# AE402FA0E5597LE0_CM55_HP_View register map
Vendor: Alif Semiconductor; Series: E4; File version: 1.0
CPU: CM55 r1p0, selectable endian, MPU, FPU, double-precision FPU, DSP, VTOR, 8 interrupt priority bits, 1 SAU regions
Registers are 32-bit, read-write, reset 0x0 unless marked. A register's access mark holds for its fields unless they carry their own. Offsets are from the block's base; [hi:lo] are bit positions; {n}, {i} and the like mark numbered series; 'fields as' and 'values as' point back to an identical list.

## ISP (part 2 of 2)
Base 0x49046000
0xA00 ISP_CC_COEFF_0 reset 0x21
  [8:0] CC_COEFF0 — Coefficient 0 for color space conversion
0xA04 ISP_CC_COEFF_1 reset 0x40
  [8:0] CC_COEFF1 — Coefficient 1 for color space conversion
0xA08 ISP_CC_COEFF_2 reset 0xD
  [8:0] CC_COEFF2 — Coefficient 2 for color space conversion
0xA0C ISP_CC_COEFF_3 reset 0x1ED
  [8:0] CC_COEFF3 — Coefficient 3 for color space conversion
0xA10 ISP_CC_COEFF_4 reset 0x1DB
  [8:0] CC_COEFF4 — Coefficient 4 for color space conversion
0xA14 ISP_CC_COEFF_5 reset 0x38
  [8:0] CC_COEFF5 — Coefficient 5 for color space conversion
0xA18 ISP_CC_COEFF_6 reset 0x38
  [8:0] CC_COEFF6 — Coefficient 6 for color space conversion
0xA1C ISP_CC_COEFF_7 reset 0x1D1
  [8:0] CC_COEFF7 — Coefficient 7 for color space conversion
0xA20 ISP_CC_COEFF_8 reset 0x1F7
  [8:0] CC_COEFF8 — Coefficient 8 for color space conversion
0xA24 ISP_FORMAT_CONV_CTRL
  [0] Y_ONLY
    0=Output y and c data from format conv; 1=Only output Y data
0xA30 ISP_CT_COEFF_0 reset 0x80
  [10:0] CT_COEFF0 — Coefficient for cross talk matrix. Values are 11-bit signed fixed-point numbers with 4 bit integer and 7 bit fractional part, ranging from -8 (0x400) to +7.992 (0x3FF). 0 is represented by 0x000 and a coefficient value of 1 as 0x080.
{0xA30+4i} ISP_CT_COEFF_{i} (i=1..3)
  [10:0] CT_COEFF{i} — Coefficient for cross talk matrix. Values are 11-bit signed fixed-point numbers with 4 bit integer and 7 bit fractional part, ranging from -8 (0x400) to +7.992 (0x3FF). 0 is represented by 0x000 and a coefficient value of 1 as 0x080.
0xA40 ISP_CT_COEFF_4 reset 0x80
  [10:0] CT_COEFF4 — Coefficient for cross talk matrix. Values are 11-bit signed fixed-point numbers with 4 bit integer and 7 bit fractional part, ranging from -8 (0x400) to +7.992 (0x3FF). 0 is represented by 0x000 and a coefficient value of 1 as 0x080.
{0xA30+4i} ISP_CT_COEFF_{i} (i=5..7)
  fields as ISP_CT_COEFF_1
0xA50 ISP_CT_COEFF_8 reset 0x80
  [10:0] CT_COEFF8 — Coefficient for cross talk matrix. Values are 11-bit signed fixed-point numbers with 4 bit integer and 7 bit fractional part, ranging from -8 (0x400) to +7.992 (0x3FF). 0 is represented by 0x000 and a coefficient value of 1 as 0x080.
0xA54 ISP_CT_OFFSET_R
  [11:0] CT_OFFSET_R — Red offset for the cross talk matrix. Two's complement integer number ranging from -2048 (0x800) to 2047 (0x7FF). 0 is represented as 0x000.
0xA58 ISP_CT_OFFSET_G
  [11:0] CT_OFFSET_G — Green offset for the cross talk matrix. Two's complement integer number ranging from -2048 (0x800) to 2047 (0x7FF). 0 is represented as 0x000.
0xA5C ISP_CT_OFFSET_B
  [11:0] CT_OFFSET_B — Blue offset for the cross talk matrix. Two's complement integer number ranging from -2048 (0x800) to 2047 (0x7FF). 0 is represented as 0x000.
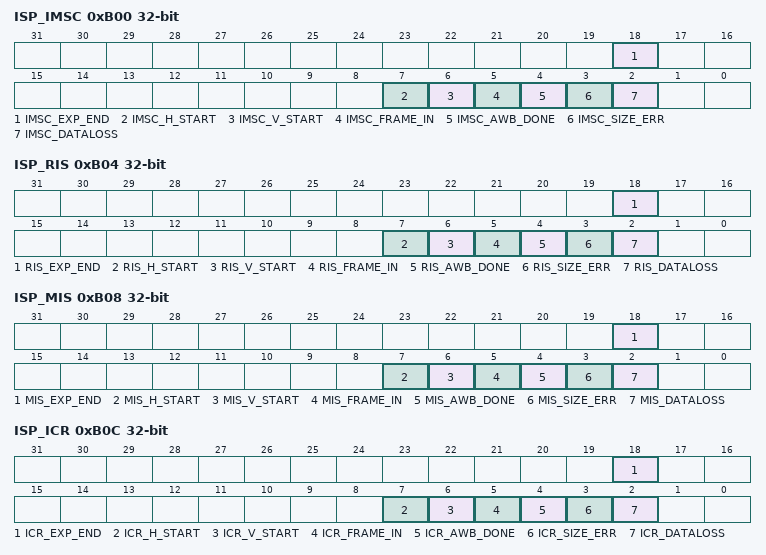
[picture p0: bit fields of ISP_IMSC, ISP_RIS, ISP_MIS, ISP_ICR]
0xB00 ISP_IMSC
  [18] IMSC_EXP_END — Exposure measurement complete
  [7] IMSC_H_START
    0=Mask out; 1=Enable interrupt
  [6] IMSC_V_START
    0=Mask out; 1=Enable interrupt
  [5] IMSC_FRAME_IN
    0=Mask out; 1=Enable interrupt
  [4] IMSC_AWB_DONE
    0=Mask out; 1=Enable interrupt
  [3] IMSC_SIZE_ERR
    0=Mask out; 1=Enable interrupt
  [2] IMSC_DATALOSS
    0=Mask out; 1=Enable interrupt
0xB04 ISP_RIS ro
  [18] RIS_EXP_END — Exposure measurement complete
  [7] RIS_H_START — Start edge of h_sync
  [6] RIS_V_START — Start edge of v_sync
  [5] RIS_FRAME_IN — Sampled input frame is complete
  [4] RIS_AWB_DONE — White balancing measurement cycle is complete results can be read out
  [3] RIS_SIZE_ERR — Picture size violation occurred incorrect programming
  [2] RIS_DATALOSS — Loss of data occurred within a line, processing failure
0xB08 ISP_MIS ro
  [18] MIS_EXP_END — Exposure measurement complete
  [7] MIS_H_START — Start edge of h_sync
  [6] MIS_V_START — Start edge of v_sync
  [5] MIS_FRAME_IN — Sampled input frame is complete
  [4] MIS_AWB_DONE — White balancing measurement cycle is complete results can be read out
  [3] MIS_SIZE_ERR — Picture size violation occurred incorrect programming
  [2] MIS_DATALOSS — Loss of data occurred within a line, processing failure
0xB0C ISP_ICR wo
  [18] ICR_EXP_END — Clear interrupt
  [7] ICR_H_START — Clear interrupt
  [6] ICR_V_START — Clear interrupt
  [5] ICR_FRAME_IN — Clear interrupt
  [4] ICR_AWB_DONE — Clear interrupt
  [3] ICR_SIZE_ERR — Clear interrupt
  [2] ICR_DATALOSS — Clear interrupt
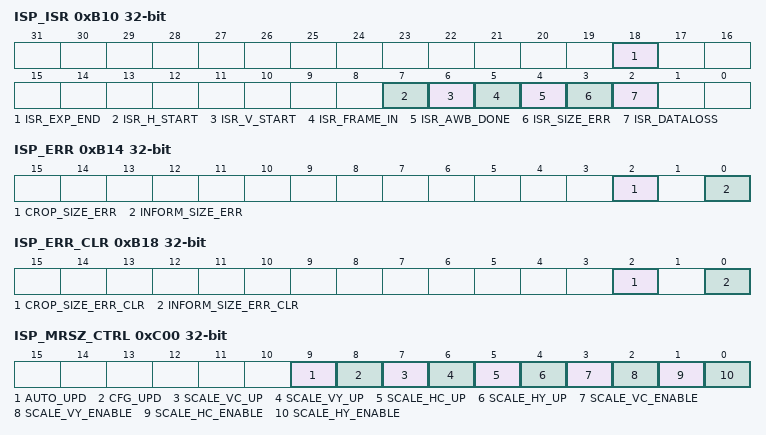
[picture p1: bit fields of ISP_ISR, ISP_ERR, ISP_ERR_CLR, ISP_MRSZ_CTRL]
0xB10 ISP_ISR wo
  [18] ISR_EXP_END — Set interrupt
  [7] ISR_H_START — Set interrupt
  [6] ISR_V_START — Set interrupt
  [5] ISR_FRAME_IN — Set interrupt
  [4] ISR_AWB_DONE — Set interrupt
  [3] ISR_SIZE_ERR — Set interrupt
  [2] ISR_DATALOSS — Set interrupt
0xB14 ISP_ERR ro
  [2] CROP_SIZE_ERR — Size error is generated in crop submodule
  [0] INFORM_SIZE_ERR — Size error is generated in inform submodule
0xB18 ISP_ERR_CLR wo
  [2] CROP_SIZE_ERR_CLR — Size error is cleared
  [0] INFORM_SIZE_ERR_CLR — Size error is cleared
0xC00 ISP_MRSZ_CTRL
  [9] AUTO_UPD
    0=No update; 1=Update shadow registers at frame end
  [8] CFG_UPD — Write 0: Nothing happens Write 1: Update shadow registers Read: Always 0
  [7] SCALE_VC_UP
    0=Vertical chrominance downscaling selected; 1=Vertical chrominance upscaling selected
  [6] SCALE_VY_UP
    0=Vertical luminance downscaling selected; 1=Vertical luminance upscaling selected
  [5] SCALE_HC_UP
    0=Horizontal chrominance downscaling selected; 1=Horizontal chrominance upscaling selected
  [4] SCALE_HY_UP
    0=Horizontal luminance downscaling selected; 1=Horizontal luminance upscaling selected
  [3] SCALE_VC_ENABLE — Vertical chrominance scaling unit
    0=Bypass; 1=Enable
  [2] SCALE_VY_ENABLE — Vertical luminance scaling unit
    0=Bypass; 1=Enable
  [1] SCALE_HC_ENABLE — Horizontal chrominance scaling unit
    0=Bypass; 1=Enable
  [0] SCALE_HY_ENABLE — Horizontal luminance scaling unit
    0=Bypass; 1=Enable
0xC04 ISP_MRSZ_SCALE_HY
  [15:0] SCALE_HY — This register is set to the horizontal luminance downscale factor or to the reciprocal of the horizontal luminance upscale factor.
0xC08 ISP_MRSZ_SCALE_HCB
  [15:0] SCALE_HCB — This register is set to the horizontal Cb downscale factor or to the reciprocal of the horizontal Cb upscale factor.
0xC0C ISP_MRSZ_SCALE_HCR
  [15:0] SCALE_HCR — This register is set to the horizontal Cr downscale factor or to the reciprocal of the horizontal Cr upscale factor.
0xC10 ISP_MRSZ_SCALE_VY
  [15:0] SCALE_VY — This register is set to the vertical luminance downscale factor or to the reciprocal of the vertical luminance upscale factor.
0xC14 ISP_MRSZ_SCALE_VC
  [15:0] SCALE_VC — This register is set to the vertical chrominance downscale factor or to the reciprocal of the vertical chrominance upscale factor.
0xC18 ISP_MRSZ_PHASE_HY
  [15:0] PHASE_HY — This register is set to the horizontal luminance phase offset.
0xC1C ISP_MRSZ_PHASE_HC
  [15:0] PHASE_HC — This register is set to the horizontal chrominance phase offset.
0xC20 ISP_MRSZ_PHASE_VY
  [15:0] PHASE_VY — This register is set to the vertical luminance phase offset.
0xC24 ISP_MRSZ_PHASE_VC
  [15:0] PHASE_VC — This register is set to the vertical chrominance phase offset.
0xC28 ISP_MRSZ_SCALE_LUT_ADDR
  [5:0] SCALE_LUT_ADDR — Pointer to entry of upscaling lookup table.
0xC2C ISP_MRSZ_SCALE_LUT
  [5:0] SCALE_LUT — Entry of lookup table at position scale_lut_addr. The lookup table must be filled with appropriate values before the upscaling functionality can be used.
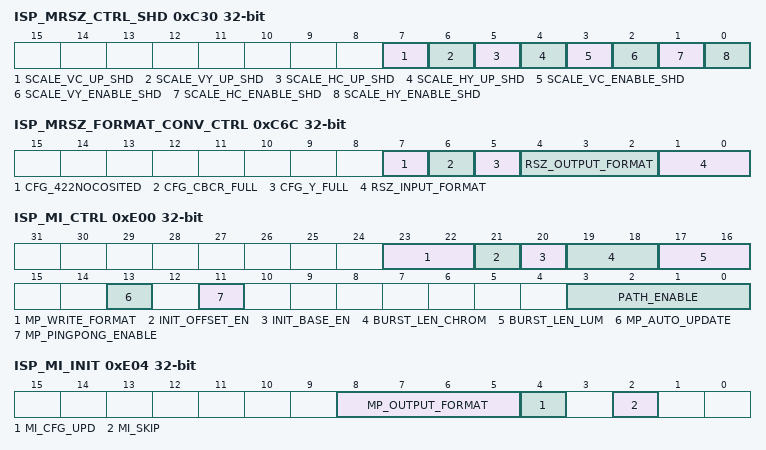
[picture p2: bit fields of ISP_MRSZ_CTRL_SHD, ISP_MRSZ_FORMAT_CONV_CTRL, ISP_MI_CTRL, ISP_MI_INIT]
0xC30 ISP_MRSZ_CTRL_SHD ro
  [7] SCALE_VC_UP_SHD
    values as ISP_MRSZ_CTRL.SCALE_VC_UP
  [6] SCALE_VY_UP_SHD
    values as ISP_MRSZ_CTRL.SCALE_VY_UP
  [5] SCALE_HC_UP_SHD
    values as ISP_MRSZ_CTRL.SCALE_HC_UP
  [4] SCALE_HY_UP_SHD
    values as ISP_MRSZ_CTRL.SCALE_HY_UP
  [3] SCALE_VC_ENABLE_SHD — Vertical chrominance scaling unit
    0=Bypass; 1=Enable
  [2] SCALE_VY_ENABLE_SHD — Vertical luminance scaling unit
    0=Bypass; 1=Enable
  [1] SCALE_HC_ENABLE_SHD — Horizontal chrominance scaling unit
    0=Bypass; 1=Enable
  [0] SCALE_HY_ENABLE_SHD — Horizontal luminance scaling unit
    0=Bypass; 1=Enable
0xC34 ISP_MRSZ_SCALE_HY_SHD ro
  [15:0] SCALE_HY_SHD — This register is set to the horizontal luminance downscale factor or to the reciprocal of the horizontal luminance upscale factor.
0xC38 ISP_MRSZ_SCALE_HCB_SHD ro
  [15:0] SCALE_HCB_SHD — This register is set to the horizontal Cb downscale factor or to the reciprocal of the horizontal Cb upscale factor.
0xC3C ISP_MRSZ_SCALE_HCR_SHD ro
  [15:0] SCALE_HCR_SHD — This register is set to the horizontal Cr downscale factor or to the reciprocal of the horizontal Cr upscale factor.
0xC40 ISP_MRSZ_SCALE_VY_SHD ro
  [15:0] SCALE_VY_SHD — This register is set to the vertical luminance downscale factor or to the reciprocal of the vertical luminance upscale factor.
0xC44 ISP_MRSZ_SCALE_VC_SHD ro
  [15:0] SCALE_VC_SHD — This register is set to the vertical chrominance downscale factor or to the reciprocal of the vertical chrominance upscale factor.
0xC48 ISP_MRSZ_PHASE_HY_SHD ro
  [15:0] PHASE_HY_SHD — This register is set to the horizontal luminance phase offset.
0xC4C ISP_MRSZ_PHASE_HC_SHD ro
  [15:0] PHASE_HC_SHD — This register is set to the horizontal chrominance phase offset.
0xC50 ISP_MRSZ_PHASE_VY_SHD ro
  [15:0] PHASE_VY_SHD — This register is set to the vertical luminance phase offset.
0xC54 ISP_MRSZ_PHASE_VC_SHD ro
  [15:0] PHASE_VC_SHD — This register is set to the vertical chrominance phase offset.
0xC6C ISP_MRSZ_FORMAT_CONV_CTRL
  [7] CFG_422NOCOSITED — so modified interpolation is activated Note: the programmed value becomes effective immediately after this register is set. Therefore, only write to this register if no picture data is sent to the Self Path.
    0=YCbCr422 data are co-sited (Y0 Cb0 and Cr0 are sampled at the same position); 1=YCbCr422 data are non_co-sited (Cb and Cr samples are centered between Y samples)
  [6] CFG_CBCR_FULL — Note: the programmed value becomes effective immediately after this register is set. Therefore, only write to this register if no picture data is sent to the Self Path.
    0=CbCr has a compressed range of [16..240]; 1=CbCr has full range [0..255]
  [5] CFG_Y_FULL — Note: the programmed value becomes effective immediately after this register is set. Therefore, only write to this register if no picture data is sent to the Self Path.
    0=Y has a compressed range of [16..235]; 1=Y has full range [0..255]
  [4:2] RSZ_OUTPUT_FORMAT — Main Resize output format Reserved
    0=Val_0b000 (YCbCr 4:0:0); 1=Val_0b001 (YCbCr 4:2:0); 2=Val_0b010 (YCbCr 4:2:2); 3=Val_0b011 (YCbCr 4:4:4); 4=Val_0b100 (RGB565,not supported); 5=Val_0b101 (RGB666,not supported); 6=Val_0b110 (RGB888)
  [1:0] RSZ_INPUT_FORMAT — Main resize input format
    0=Val_0b00 (YCbCr 4:0:0); 1=Val_0b01 (YCbCr 4:2:0); 2=Val_0b10 (YCbCr 4:2:2); 3=Val_0b11 (YCbCr 4:4:4)
0xE00 ISP_MI_CTRL
  [23:22] MP_WRITE_FORMAT — Defines how YCbCr main picture data is written to memory. In YCbCr mode the following meaning is applicable: 00: Planar 01: Semi planar, for YCbCr 4:2:x 10: Interleaved (combined), for YCbCr 4:2:2 only 11: YUV only In RAW data mode the following meaning is applicable: 00: RAW 8 bit 01: RAW 10 bit 10: RAW 12bit 11: Reserved Note: Programmed value becomes effective immediately. So write to the register only if no picture data is sent to the main path.
  [21] INIT_OFFSET_EN — Enables updating of the offset counters shadow registers for main and self picture to the programmed register init values. MI_MP/SP_Y/CB/CR_OFFS_CNT_INIT-&gt MI_MP/SP_Y/CB/CR_OFFS_CNT_SHD The update will be executed either when a forced software update occurs (in register ISP_MI_INIT bit cfg_upd = 1) or when an automatic config update signal arrives at the MI input port. The latter is split into main and self picture. So only the corresponding main/self shadow registers are affected. After a picture skip has been performed init_offset_en selects between skip restart and skip init mode (see bit skip in register ISP_MI_INIT).
  [20] INIT_BASE_EN — Enables updating of the base address and buffer size shadow registers for main and self picture to the programmed register init values. MI_MP/SP_Y/CB/CR_BASE_AD_INIT -&gt MI_MP/SP_Y/CB/CR_BASE_AD_SHD MI_MP/SP_Y/CB/CR_SIZE_INIT-&gt MI_MP/SP_Y/CB/CR_SIZE_SHD The update will be executed either when a forced software update occurs (in register ISP_MI_INIT bit cfg_upd = 1) or when an automatic config update signal arrives at the MI input port. The latter is split into main and self picture. So only the corresponding main/self shadow registers are affected.
  [19:18] BURST_LEN_CHROM — Burst length for Cb or Cr data affecting write port. Ignored if 8- or 16-beat bursts are not supported. If rotation is active, then only 4-beat bursts will be generated in self path, regardless of the setting here. Note: Programmed value becomes effective immediately. So write to the register only if no picture data is sent to the main and self path.
    0=Val_0b00 (4-beat bursts); 1=Val_0b01 (8-beat bursts); 2=Val_0b10 (16-beat bursts)
  [17:16] BURST_LEN_LUM — Burst length for Y, JPEG, or raw data affecting write port. Ignored if 8- or 16-beat bursts are not supported. Note: Programmed value becomes effective immediately. So write to the register only if no picture data is sent to the main and self path.
    values as BURST_LEN_CHROM
  [13] MP_AUTO_UPDATE — Automatic update of configuration registers for main path at frame end.
    0=Disabled; 1=Enabled
  [11] MP_PINGPONG_ENABLE — Pingpong mode of configuration registers for main path at frame end.
    0=Disabled; 1=Enabled
  [3:0] PATH_ENABLE — Enables data paths of Memory Interface according to the following table: The programmed value becomes effective (visible in shadow register) after a soft reset, a forced software update or an automatic configuration update. Affects the MI_IN and MI_OUT module.
    0=Val_0b0000 (Disabled, no data is transferred); 1=Val_0b0001 (YUV data output, mainpath only (mp_enable only)); 8=Val_0b1000 (RAW data output, mainpath only (raw_enable only))
0xE04 ISP_MI_INIT
  [8:5] MP_OUTPUT_FORMAT — Selects output format of main picture.
    0=Val_0b0000 (YCbCr 4:0:0); 1=Val_0b0001 (YCbCr 4:2:0); 2=Val_0b0010 (YCbCr 4:2:2); 5=Val_0b0101 (RAW 8); 4=Val_0b0100 (RAW 12); 7=Val_0b0111 (RAW 10)
  [4] MI_CFG_UPD — Forced configuration update. Leads to an immediate update of the shadow registers. Depending on the two init enable bits in the ISP_MI_CTRL register (init_offset_en and init_base_en) the offset counter, base address and buffer size shadow registers are also updated.
  [2] MI_SKIP — Skip of current or next starting main picture: - Aborts writing of main picture image data of the current frame to RAM (after the current burst transmission has been completed). Further main picture data up to the end of the current frame are discarded. - No further macroblock line interrupt (mblk_line), no wrap around interrupt for main picture (wrap_mp_y/cb/cr) and no fill level interrupt (fill_mp_y) are generated. - Skip does not affect the generation of the main path frame end interrupt (mp_frame_end). - Skip does not affect the processing of self picture and its corresponding interrupts namely the self path frame end interrupt (sp_frame_end). - The byte counter (register ISP_MI_BYTE_CNT) is not affected. It produces the correct number of JPEG or RAW data bytes at the end of the current (skipped) frame. - After a skip has been performed, the offset counter for the main picture at the start of the following frame are set depending on the bit init_offset_en in register ISP_MI_CTRL: - Skip restart mode (init_offset_en = 0) The offset counters of the main picture are restarted at the old start values of the previous skipped frame. - Skip init mode (init_offset_en = 1) The offset counters of the main picture are initialized with the register contents of the offset counter init registers without any additional forced software update or automatic config update.
0xE08 ISP_MI_MP_Y_BASE_AD_INIT
  [31:3] MP_Y_BASE_AD_INIT — Base address of main picture Y component ring buffer, JPEG ring buffer or raw data ring buffer. Programmed value becomes effective (visible in corresponding shadow register) after a soft reset, a forced software update or an automatic configuration update.
0xE0C ISP_MI_MP_Y_SIZE_INIT
  [28:3] MP_Y_SIZE_INIT — Size of main picture Y component ring buffer, JPEG ring buffer or raw data ring buffer. Programmed value becomes effective (visible in corresponding shadow register) after a soft reset, a forced software update or an automatic configuration update.
0xE10 ISP_MI_MP_Y_OFFS_CNT_INIT
  [28:3] MP_Y_OFFS_CNT_INIT — Offset counter init value of main picture Y component ring buffer, JPEG ring buffer or raw data ring buffer. Programmed value becomes effective (visible in corresponding shadow register) after a soft reset, a forced software update or an automatic configuration update.
0xE14 ISP_MI_MP_Y_OFFS_CNT_START ro
  [28:3] MP_Y_OFFS_CNT_START — Offset counter value which points to the start address of the previously processed picture (main picture Y component, JPEG or raw data). Updated at frame end. Note: A soft reset resets the contents to the reset value.
0xE18 ISP_MI_MP_Y_IRQ_OFFS_INIT
  [28:3] MP_Y_IRQ_OFFS_INIT — Reaching this programmed value by the current offset counter for addressing main picture Y component, JPEG or raw data leads to the generation of fill level interrupt fill_mp_y. Programmed value becomes effective (visible in corresponding shadow register) after a soft reset, a forced software update or an automatic configuration update.
0xE1C ISP_MI_MP_CB_BASE_AD_INIT
  [31:3] MP_CB_BASE_AD_INIT — Base address of main picture Cb component ring buffer. Programmed value becomes effective (visible in corresponding shadow register) after a soft reset, a forced software update or an automatic config update. Note: Set control bit init_base_en before updating so that a forced or automatic update can take effect.
0xE20 ISP_MI_MP_CB_SIZE_INIT
  [27:3] MP_CB_SIZE_INIT — Size of main picture Cb component ring buffer. Programmed value becomes effective (visible in corresponding shadow register) after a soft reset, a forced software update or an automatic config update. Note: Set control bit init_base_en before updating so that a forced or automatic update can take effect.
0xE24 ISP_MI_MP_CB_OFFS_CNT_INIT
  [27:3] MP_CB_OFFS_CNT_INIT — Offset counter init value of main picture Cb component ring buffer. Programmed value becomes effective (visible in corresponding shadow register) after a soft reset, a forced software update or an automatic configuration update. Note: Set control bit init_base_en before updating so that a forced or automatic update can take effect. Check exceptionhandling in skip modes.
0xE28 ISP_MI_MP_CB_OFFS_CNT_START ro
  [27:3] MP_CB_OFFS_CNT_START — Offset counter value which points to the start address of the previously processed picture (main picture Cb component). Updated at frame end.
0xE2C ISP_MI_MP_CR_BASE_AD_INIT
  [31:3] MP_CR_BASE_AD_INIT — Base address of main picture Cr component ring buffer. Programmed value becomes effective (visible in corresponding shadow register) after a soft reset, a forced software update or an automatic config update. Note: Set control bit init_base_en before updating so that a forced or automatic update can take effect.
0xE30 ISP_MI_MP_CR_SIZE_INIT
  [27:3] MP_CR_SIZE_INIT — Size of main picture Cr component ring buffer. Programmed value becomes effective (visible in corresponding shadow register) after a soft reset, a forced software update or an automatic configuration update. Note: Set control bit init_base_en before updating so that a forced or automatic update can take effect.
0xE34 ISP_MI_MP_CR_OFFS_CNT_INIT
  [27:3] MP_CR_OFFS_CNT_INIT — Offset counter init value of main picture Cr component ring buffer. Programmed value becomes effective (visible in corresponding shadow register) after a soft reset, a forced software update or an automatic configuration update. Note: Set control bit init_base_en before updating so that a forced or automatic update can take effect. Check exception handling in skip modes.
0xE38 ISP_MI_MP_CR_OFFS_CNT_START ro
  [27:3] MP_CR_OFFS_CNT_START — Offset counter value which points to the start address of the previously processed picture (main picture Cr component). Updated at frame end. Note: Soft reset will reset the contents to the reset value.
0xE70 ISP_MI_BYTE_CNT ro
  [27:0] BYTE_CNT — Counter value specifies the number of JPEG or RAW data bytes of the last transmitted frame. Updated at frame end. A soft reset will set the byte counter to zero.
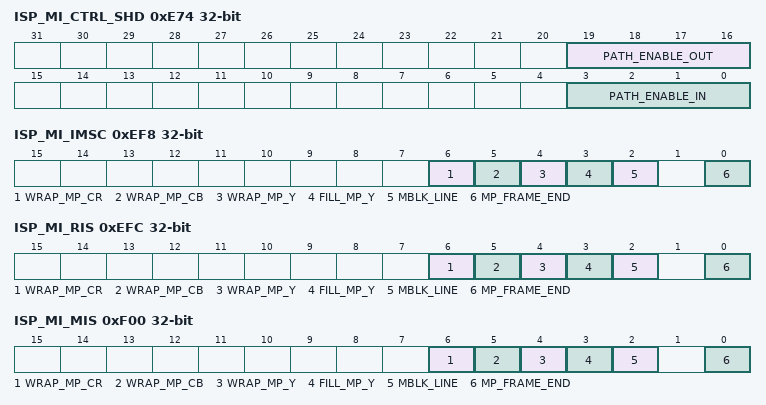
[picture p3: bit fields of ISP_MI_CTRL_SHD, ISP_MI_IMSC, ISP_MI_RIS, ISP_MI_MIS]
0xE74 ISP_MI_CTRL_SHD ro
  [19:16] PATH_ENABLE_OUT — Path_enable shadow register for module MI_OUT (former raw_enable_out, jpeg_enable_out, sp_enable_out, mp_enable_out)
  [3:0] PATH_ENABLE_IN — Path_enable shadow register for module MI_IN (former raw_enable_in, jpeg_enable_in, sp_enable_in, mp_enable_in)
0xE78 ISP_MI_MP_Y_BASE_AD_SHD ro
  [31:3] MP_Y_BASE_AD — Base address of main picture Y component ring buffer, JPEG ring buffer or raw data ring buffer.
0xE7C ISP_MI_MP_Y_SIZE_SHD ro
  [28:3] MP_Y_SIZE — Size of main picture Y component ring buffer, JPEG ring buffer or raw data ring buffer.
0xE80 ISP_MI_MP_Y_OFFS_CNT_SHD ro
  [28:3] MP_Y_OFFS_CNT — Current offset counter of main picture Y component, JPEG or raw data ring buffer for address generation. Note: Soft reset will reset the contents to the reset value.
0xE84 ISP_MI_MP_Y_IRQ_OFFS_SHD ro
  [28:3] MP_Y_IRQ_OFFS — Reaching this offset value by the current offset counter for addressing the main picture Y component, JPEG or raw data leads to the generation of fill level interrupt fill_mp_y.
0xE88 ISP_MI_MP_CB_BASE_AD_SHD ro
  [31:3] MP_CB_BASE_AD — Base address of main picture Cb component ring buffer.
0xE8C ISP_MI_MP_CB_SIZE_SHD ro
  [27:3] MP_CB_SIZE — Size of main picture Cb component ring buffer.
0xE90 ISP_MI_MP_CB_OFFS_CNT_SHD ro
  [27:3] MP_CB_OFFS_CNT — Current offset counter of main picture Cb component ring buffer for address generation. Note: Soft reset will reset the contents to the reset value.
0xE94 ISP_MI_MP_CR_BASE_AD_SHD ro
  [31:3] MP_CR_BASE_AD — Base address of main picture Cr component ring buffer.
0xE98 ISP_MI_MP_CR_SIZE_SHD ro
  [27:3] MP_CR_SIZE — Size of main picture Cr component ring buffer.
0xE9C ISP_MI_MP_CR_OFFS_CNT_SHD ro
  [27:3] MP_CR_OFFS_CNT — Current offset counter of main picture Cr component ring buffer for address generation. Note: Soft reset will reset the contents to the reset value.
0xEF8 ISP_MI_IMSC
  [6] WRAP_MP_CR — Mask bit for main picture Cr address wrap interrupt
  [5] WRAP_MP_CB — Mask bit for main picture Cb address wrap interrupt
  [4] WRAP_MP_Y — Mask bit for main picture Y address wrap interrupt
  [3] FILL_MP_Y — Mask bit for fill level interrupt of main picture Y, JPEG or raw data
  [2] MBLK_LINE — Mask bit for macroblock line interrupt of main picture (16 lines of Y, 8 lines of Cb and 8 lines of Cr are written into RAM)
  [0] MP_FRAME_END — Mask main picture end of frame interrupt
0xEFC ISP_MI_RIS ro
  [6] WRAP_MP_CR — Raw status of main picture Cr address wrap interrupt
  [5] WRAP_MP_CB — Raw status of main picture Cb address wrap interrupt
  [4] WRAP_MP_Y — Raw status of main picture Y address wrap interrupt
  [3] FILL_MP_Y — Raw status of fill level interrupt of main picture Y, JPEG or raw data
  [2] MBLK_LINE — Raw status of macroblock line interrupt of main picture (16 lines of Y, 8 lines of Cb and 8 lines of Cr are written into RAM valid only for planar and semi-planar mode)
  [0] MP_FRAME_END — Raw status of main picture end of frame interrupt
0xF00 ISP_MI_MIS ro
  [6] WRAP_MP_CR — Masked status of main picture Cr address wrap interrupt
  [5] WRAP_MP_CB — Masked status of main picture Cb address wrap interrupt
  [4] WRAP_MP_Y — Masked status of main picture Y address wrap interrupt
  [3] FILL_MP_Y — Masked status of fill level interrupt of main picture Y, JPEG or raw data
  [2] MBLK_LINE — Masked status of macroblock line interrupt of main picture (16 lines of Y, 8 lines of Cb and 8 lines of Cr are written into RAM, valid only for planar and semi-planar mode)
  [0] MP_FRAME_END — Masked status of main picture end of frame interrupt
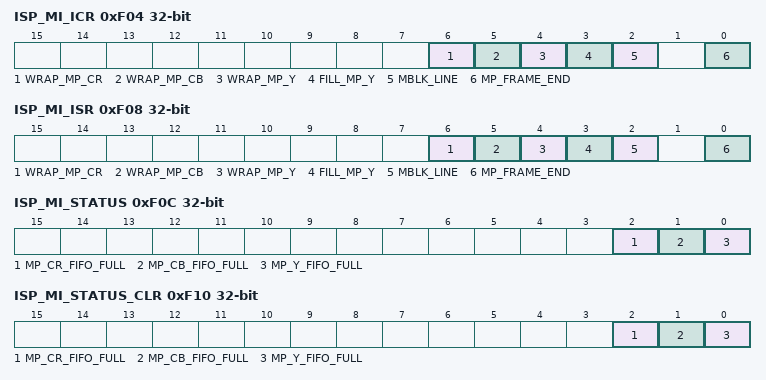
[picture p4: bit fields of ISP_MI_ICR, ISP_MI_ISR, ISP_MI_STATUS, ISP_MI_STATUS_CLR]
0xF04 ISP_MI_ICR wo
  [6] WRAP_MP_CR — Clear main picture Cr address wrap interrupt
  [5] WRAP_MP_CB — Clear main picture Cb address wrap interrupt
  [4] WRAP_MP_Y — Clear main picture Y address wrap interrupt
  [3] FILL_MP_Y — Clear fill level interrupt
  [2] MBLK_LINE — Clear macroblock line interrupt
  [0] MP_FRAME_END — Clear main picture end of frame interrupt
0xF08 ISP_MI_ISR wo
  [6] WRAP_MP_CR — Set main picture Cr address wrap interrupt
  [5] WRAP_MP_CB — Set main picture Cb address wrap interrupt
  [4] WRAP_MP_Y — Set main picture Y address wrap interrupt
  [3] FILL_MP_Y — Set fill level interrupt
  [2] MBLK_LINE — Set macroblock line interrupt
  [0] MP_FRAME_END — Set main picture end of frame interrupt
0xF0C ISP_MI_STATUS ro
  [2] MP_CR_FIFO_FULL — FIFO full flag of Cr FIFO in main path asserted since last clear
  [1] MP_CB_FIFO_FULL — FIFO full flag of Cb FIFO in main path asserted since last clear
  [0] MP_Y_FIFO_FULL — FIFO full flag of Y FIFO in main path asserted since last clear
0xF10 ISP_MI_STATUS_CLR wo
  [2] MP_CR_FIFO_FULL — Clear status of Cr FIFO full flag in main path
  [1] MP_CB_FIFO_FULL — Clear status of Cb FIFO full flag in main path
  [0] MP_Y_FIFO_FULL — Clear status of Y FIFO full flag in main path
0xF30 ISP_MI_MP_Y_BASE_AD_INIT2
  [31:3] MP_Y_BASE_AD_INIT2 — 2nd ping pong base address of main picture Y component buffer, JPEG buffer or raw data buffer. Programmed value becomes effective (visible in corresponding shadow register) after a soft reset, a forced software update or an automatic configure update. Note: Set control bit ISP_MI_CTRL.init_base_en[bit 20] before updating so that a forced or automatic update can take effect.
0xF34 ISP_MI_MP_CB_BASE_AD_INIT2
  [31:3] MP_CB_BASE_AD_INIT2 — 2nd ping pong base address of main picture Cb component buffer. Programmed value becomes effective (visible in corresponding shadow register) after a soft reset, a forced software update or an automatic configure update. Note: Set control bit ISP_MI_CTRL.init_base_en[bit 20] before updating so that a forced or automatic update can take effect.
0xF38 ISP_MI_MP_CR_BASE_AD_INIT2
  [31:3] MP_CR_BASE_AD_INIT2 — 2nd ping pong base address of main picture Cr component buffer. Programmed value becomes effective (visible in corresponding shadow register) after a soft reset, a forced software update or an automatic configure update. Note: Set control bit ISP_MI_CTRL.init_base_en[bit 20] before updating so that a forced or automatic update can take effect.
0xF50 ISP_MI_MP_Y_LLENGTH
  [14:0] MP_Y_LLENGH — Line length of main picture Y component in pixel, also known as line stride. If no line stride is used, line length must match image width. For the main picture Y component, the line length in 4:2:x planar mode must be a multiple of 8 for all other component modes, the line length must be a multiple of 4 In planar mode, the line length of the Cb and Cr component is assumed according to the YCbCr format, i.e. half for 4:2:x and the same size for 4:4:4. In semi planar 4:2:x mode, the line length of the Cb and Cr component is assumed to be the same size.
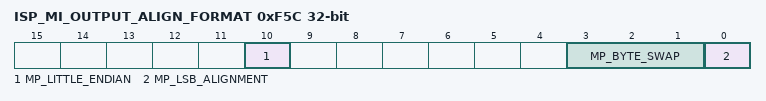
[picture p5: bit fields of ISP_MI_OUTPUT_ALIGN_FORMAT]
0xF5C ISP_MI_OUTPUT_ALIGN_FORMAT
  [10] MP_LITTLE_ENDIAN
    1=Little endian; 0=Big endian
  [3:1] MP_BYTE_SWAP — Swap bytes: Bit 0 to swap bytes Bit 1 to swap words Bit 2 to swap dwords ABCDEFGH BADCFEHG CDABGHEF DCBAHGFE EFGHABCD FEHGBADC GHEFCDAB HGFEDCBA
    0=Val_0b000 (ABCDEFGH =&gt); 1=Val_0b001 (ABCDEFGH =&gt); 2=Val_0b010 (ABCDEFGH =&gt); 3=Val_0b011 (ABCDEFGH =&gt); 4=Val_0b100 (ABCDEFGH =&gt); 5=Val_0b101 (ABCDEFGH =&gt); 6=Val_0b110 (ABCDEFGH =&gt); 7=Val_0b111 (ABCDEFGH =&gt)
  [0] MP_LSB_ALIGNMENT
    0=MSB aligned for RAW10 and RAW12 formats; 1=LSB aligned for RAW10 and RAW12 formats
0xF60 ISP_MI_MP_OUTPUT_FIFO_SIZE
  [1:0] MP_OUTPUT_FIFO_SIZE — Select Output FIFO depth setting
    0=Val_0b00 (FULL (2 KBytes)); 1=Val_0b01 (HALF (1 KByte)); 2=Val_0b10 (1/4 (512 Bytes)); 3=Val_0b11 (1/8 (256 Bytes))
0xF64 ISP_MI_MP_Y_PIC_WIDTH
  [31:0] MP_Y_PIC_WIDTH — Image width of the main picture Y component in pixel. For YCbCr 4:2:x the image width must be a multiple of 2. In planar mode the image width of the Cb and Cr component is assumed according to the YCbCr format, i.e. half for 4:2:x and the same size for 4:4:4. In semi planar 4:2:x mode the image width of the Cb component (which includes Cr) is assumed the same size. In interleave mode no Cb/Cr image width is used.
0xF68 ISP_MI_MP_Y_PIC_HEIGHT
  [31:0] MP_Y_PIC_HEIGHT — Image height of the y component in pixel. In planar and semi planar mode the image height of the Cb and Cr component is assumed according to the YCbCr format, i.e. half for 4:2:0 and the same for 4:2:2 and 4:4:4.
0xF6C ISP_MI_MP_Y_PIC_SIZE
  [31:0] MP_Y_PIC_SIZE — Image size of the Y component in pixel which has to be the Y line length multiplied by the Y image height (mp_y_llength * mp_y_pic_height). In planar mode the image size of the Cb and Cr component is assumed according to the YCbCr format, i.e. a quarter for 4:2:0, half for 4:2:2 and the same for 4:4:4. In semi planar mode the image size of the Cb and Cr component is assumed half for 4:2:0 and the same size for 4:2:2.
